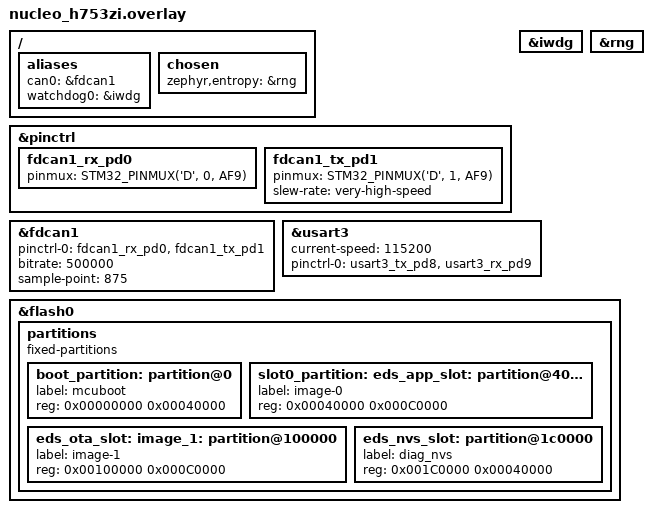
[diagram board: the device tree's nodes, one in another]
/*
 * =============================================================================
 * Xaloqi EDS
 * boards/nucleo_h743zi/nucleo_h743zi.overlay
 *
 * Device Tree overlay for the STMicroelectronics NUCLEO-H743ZI2 board.
 *
 * PURPOSE: Configures the STM32H743's FDCAN1 peripheral as the diagnostic
 *          CAN channel. FDCAN1 is wired to the CN10 connector on the
 *          NUCLEO-H743ZI2 board, where a CAN transceiver (e.g. TJA1051)
 *          must be connected externally.
 *
 * HARDWARE SETUP:
 *   NUCLEO-H743ZI2 → CAN Transceiver (TJA1051 or equivalent)
 *   PD0  (FDCAN1_RX)  → TJA1051 RXD
 *   PD1  (FDCAN1_TX)  → TJA1051 TXD
 *   3.3V               → TJA1051 VCC (via 3.3V regulator)
 *   GND                → TJA1051 GND
 *   TJA1051 CANH/CANL → OBD-II or automotive CAN bus
 *
 * CAN BUS PARAMETERS:
 *   Bus speed: 500 kbit/s  (ISO 15765-4 §4.2 for 11-bit CAN IDs)
 *   Sample point: 87.5%   (matches CANopen and automotive ECU convention)
 *
 * PINMUX:
 *   PD0 / PD1 are the default FDCAN1 pins on STM32H7 series.
 *   Alternative pins (PH13/PH14 on NUCLEO-H743ZI2 CN10) can be used by
 *   replacing pinctrl-0 with &fdcan1_rx_ph13 and &fdcan1_tx_ph14.
 *
 * WATCHDOG:
 *   The IWDG (Independent Watchdog) is enabled with a 100 ms window,
 *   matching CONFIG_DIAG_WDT_WINDOW_MS in prj.conf.
 *   The IWDG clock source is LSI (~32 kHz); prescaler and reload values
 *   are computed by the Zephyr IWDG driver from the window-ms property.
 *
 * SAFETY: This overlay is a starting point. OEM integration must:
 *   [ ] Verify PD0/PD1 pinout against actual board schematic
 *   [ ] Validate 500 kbit/s sample point against network analyser
 *   [ ] Enable CAN termination resistor (120 Ω) on bus endpoints
 *   [ ] Qualify FDCAN1 against ISO 11898-1 electrical requirements
 * =============================================================================
 */

#include <zephyr/dt-bindings/pinctrl/stm32-pinctrl.h>

/* ── Pin control for FDCAN1 ────────────────────────────────────────────────
 *
 * PD0 = FDCAN1_RX (AF9)
 * PD1 = FDCAN1_TX (AF9)
 *
 * Both pins configured as:
 *   - slew-rate = "very-high-speed"  (required for CAN signal integrity)
 *   - drive-open-drain = no          (push-pull for TX, input for RX)
 * ─────────────────────────────────────────────────────────────────────────── */
&pinctrl {
	fdcan1_rx_pd0: fdcan1_rx_pd0 {
		pinmux = <STM32_PINMUX('D', 0, AF9)>;
	};
	fdcan1_tx_pd1: fdcan1_tx_pd1 {
		pinmux = <STM32_PINMUX('D', 1, AF9)>;
		slew-rate = "very-high-speed";
	};
};

/* ── FDCAN1 node ────────────────────────────────────────────────────────────
 *
 * Configures the STM32H743 FDCAN1 controller for classic CAN 2.0B operation
 * at 500 kbit/s. FDCAN FD-mode is deliberately disabled (classic frames only)
 * to match ISO 15765-4 11-bit addressing requirements.
 * ─────────────────────────────────────────────────────────────────────────── */
&fdcan1 {
	status = "okay";
	pinctrl-0 = <&fdcan1_rx_pd0 &fdcan1_tx_pd1>;
	pinctrl-names = "default";

	/*
	 * Sample point = 87.5% — standard automotive ECU configuration.
	 * Computed as: (1 + prop-seg + phase-seg1) / (1 + prop-seg + phase-seg1 + phase-seg2)
	 *
	 * With FDCAN1 kernel clock at 80 MHz and prescaler=1:
	 *   Bit time = 160 time quanta (TQ)
	 *   prop-seg + phase-seg1 = 139 TQ
	 *   phase-seg2            =  20 TQ
	 *   Sample point = 140/160 = 87.5%
	 *
	 * FIX (#309): `bus-speed` was REMOVED here, on the belief that it was
	 *      deprecated-and-dropped and that bus speed comes from the clock
	 *      tree. Both were wrong. Zephyr's dts/bindings/can/can-controller.yaml
	 *      says bus-speed was "renamed to bitrate" — a rename, not a removal —
	 *      and that when no bitrate property is present the controller falls
	 *      back to CONFIG_CAN_DEFAULT_BITRATE, whose Zephyr default is
	 *      125000. So this node silently ran the diagnostic bus at 125 kbit/s
	 *      while every doc, comment and TestLab campaign specified 500 kbit/s,
	 *      and no tester following the documentation could talk to the ECU.
	 *      Measured on target before the fix: FDCAN1_NBTP = 0x12038A13, i.e.
	 *      NBRP=3 (prescaler 4) x 160 tq @ 80 MHz = 125 kbit/s.
	 *      Use `bitrate` (below); do not delete it to silence a deprecation.
	 * FIX: rx-fifo0-elements and tx-fifo-elements removed — these properties are
	 *      not declared in st,stm32h7-fdcan.yaml for Zephyr 3.7 and cause a
	 *      fatal gen_defines.py error: "not declared in 'properties:'".
	 */
	bitrate      = <500000>;   /* ISO 15765-4 diagnostic bus speed */
	sample-point = <875>;
};

/* ── Alias: can0 → fdcan1 ───────────────────────────────────────────────────
 *
 * main.c uses DEVICE_DT_GET(DT_ALIAS(can0)) — this alias maps that to FDCAN1.
 * ─────────────────────────────────────────────────────────────────────────── */
/ {
	aliases {
		can0 = &fdcan1;
		watchdog0 = &iwdg;
	};
};

/* ── Independent Watchdog (IWDG) ────────────────────────────────────────────
 *
 * STM32H743 IWDG is clocked by LSI (~32 kHz, factory-trimmed to ±10%).
 * The Zephyr IWDG driver converts the wdt_timeout_cfg.window.max value
 * (in ms) to prescaler and reload register values automatically.
 *
 * 100 ms window: gives 100 poll iterations at 1 ms/iteration before reset.
 * ─────────────────────────────────────────────────────────────────────────── */
&iwdg {
	status = "okay";
};

/* ── Hardware RNG (STM32H743 true random number generator) ─────────────────
 *
 * Enables the STM32H743ZI hardware RNG peripheral and maps it to the
 * zephyr,entropy chosen node. This allows CONFIG_ENTROPY_GENERATOR=y to
 * link the entropy driver and provide TRNG-backed seed generation for the
 * UDS SecurityAccess AES-CMAC algorithm (Phase 1).
 *
 * The STM32H743ZI has a 32-bit hardware TRNG (HASH/RNG block) seeded by
 * multiple on-chip analogue noise sources. Zephyr driver: st,stm32-rng.
 *
 * FIX (Phase 1 CI): CONFIG_ENTROPY_GENERATOR=y is now set in nucleo_h743zi.conf.
 *   Without this node, DT_HAS_CHOSEN(zephyr_entropy)=1 (built-in board DTS)
 *   but the entropy driver would not be linked → __device_dts_ord_N undefined.
 * ─────────────────────────────────────────────────────────────────────────── */
&rng {
	status = "okay";
};

/ {
	chosen {
		zephyr,entropy = &rng;
	};
};

/* ── UART3 for logging (ST-Link virtual COM port on NUCLEO-H743ZI2) ─────── */
&usart3 {
	status = "okay";
	current-speed = <115200>;
	pinctrl-0 = <&usart3_tx_pd8 &usart3_rx_pd9>;
	pinctrl-names = "default";
};

/* ── NVS flash partition for platform/nvm_store.c ───────────────────────────
 *
 * Reserves the last two 128 KB sectors (256 KB total) of the STM32H743ZI's
 * 2 MB internal flash for Zephyr NVS (Non-Volatile Storage).
 *
 * STM32H743ZI dual-bank flash layout (2 MB total, base 0x08000000):
 *   Bank 1: sectors 0–7  → 0x08000000 – 0x080FFFFF  (8 × 128 KB)
 *   Bank 2: sectors 8–15 → 0x08100000 – 0x081FFFFF  (8 × 128 KB)
 *
 * NVS partition occupies the last 2 sectors of Bank 2:
 *   Flash-relative offset: 0x001C0000  (1.75 MB from flash base)
 *   Size: 0x00040000  (256 KB = 2 × 128 KB sectors)
 *   Physical address: 0x081C0000 – 0x081FFFFF
 *
 * Zephyr NVS requires a minimum of 2 sectors for wear levelling.
 * Two 128 KB sectors provide ample space for the six NVM keys used by this
 * application (security counters, DTC mirror, session stats, lifecycle
 * counter, schema version — all well under 1 KB total).
 *
 * nvm_store_init() receives the flash device pointer and partition offset at
 * runtime via the nvm_store_cfg_t parameter passed from main.c using the
 * FIXED_PARTITION_DEVICE(diag_nvs) and FIXED_PARTITION_OFFSET(diag_nvs)
 * DTS accessor macros.
 *
 * NOTE: The application firmware image must remain below 768 KB (0xC0000
 * bytes, the image-0 slot size below) to avoid overwriting image-1. The
 * basic_ecu firmware is comfortably within this limit (< 256 KB for a
 * typical Zephyr application).
 * =============================================================================
 */
/* ── Flash partition table ───────────────────────────────────────────────────
 *
 * STM32H753ZI dual-bank flash: 2 MB total, base 0x08000000.
 *   Bank 1: sectors 0–7  → 0x08000000–0x080FFFFF  (8 × 128 KB)
 *   Bank 2: sectors 8–15 → 0x08100000–0x081FFFFF  (8 × 128 KB)
 *
 * Layout (exactly 2 MB, every boundary on a 128 KB sector edge):
 *
 *   Offset     Size    Sectors  Label        Purpose
 *   ─────────  ──────  ───────  ───────────  ─────────────────────────────
 *   0x000000   256 KB  2        boot_partition  MCUboot itself (measured
 *                                                ~44.8 KB signed w/ RSA-2048;
 *                                                256 KB leaves headroom).
 *   0x040000   768 KB  6        image-0      Primary firmware slot.
 *   0x100000   768 KB  6        image-1      Secondary / OTA staging slot.
 *                                            platform/zephyr_flash_ops.c
 *                                            writes DFU payloads here via
 *                                            FLASH_AREA_ID(image_1).
 *   0x1C0000   256 KB  2        diag_nvs     Zephyr NVS (security counters,
 *                                            DTC mirror, session stats).
 *                                            Needs ≥ 2 sectors for WL.
 *
 * FIX (H753ZI bring-up, 2026-09-25): previous layout had NO boot_partition —
 * image-0 started at flash base 0x0, identical to where MCUboot's own build
 * also links (zephyr,code-partition resolves to whatever &boot_partition or
 * &slot0_partition points at; with no boot_partition node, MCUboot silently
 * fell back to slot0_partition and would have overwritten the app image on
 * flash, confirmed by inspecting a real MCUboot build's .config
 * (CONFIG_FLASH_LOAD_OFFSET=0x0, same as the app). image-0/image-1 shrank
 * from 896 KB to 768 KB each to make room while keeping every partition
 * boundary sector-aligned — 896/192/64 KB splits are NOT multiples of the
 * 128 KB hardware sector size, which would let a sector erase (NVS wear-
 * levelling, or MCUboot's own writes) corrupt the tail of the neighbouring
 * partition. slot0/slot1 MUST stay equal size (MCUboot swap requirement).
 *
 * FIX (CI 2026-03-30): previous layout had label "mcuboot" on the app slot and
 * no image-1 partition. FLASH_AREA_ID(image_1) in zephyr_flash_ops.c requires
 * a partition labelled "image-1" to exist in the DTS; without it the macro
 * expands to an undeclared identifier → compile error. CONFIG_FLASH_MAP=y is
 * already set in nucleo_h743zi.conf; the DTS label was the only missing piece.
 */
&flash0 {
	/* [FIX] Delete the existing partitions node defined in the Zephyr base board DTS
	 * (nucleo_h743zi2.dts) before redefining it.  The base DTS already has a node
	 * labelled slot0_partition at partition@40000.  Our overlay was adding another
	 * slot0_partition at partition@0, causing:
	 *   devicetree error: Label 'slot0_partition' appears on partition@0 AND partition@40000
	 * Fix: /delete-node/ removes the existing child, then we redefine from scratch
	 * using unique DTS node names (eds_app_slot, eds_ota_slot, eds_nvs_slot) that
	 * cannot conflict with the base board DTS.
	 * FLASH_AREA_ID() resolves by the "label" property string, not the DTS node name,
	 * so FLASH_AREA_ID(image_1) still resolves correctly. */
	/delete-node/ partitions;

	partitions {
		compatible = "fixed-partitions";
		#address-cells = <1>;
		#size-cells = <1>;

		/* MCUboot itself — 256 KB (2 sectors) at flash base. Required so
		 * zephyr,code-partition resolves to &boot_partition (not
		 * &slot0_partition) when MCUboot's OWN build applies its
		 * bootloader/mcuboot/boot/zephyr/app.overlay, which sets exactly
		 * that chosen override. Without this node that override dangles
		 * and MCUboot silently falls back to whatever /chosen already
		 * pointed at (slot0_partition) — linking MCUboot at the same
		 * address as the app image. See the FIX note above the flash
		 * partition table for how this was caught on real hardware. */
		boot_partition: partition@0 {
			label = "mcuboot";
			reg = <0x00000000 0x00040000>;
		};

		/* Primary firmware image slot — 768 KB, starting after boot_partition.
		 * Dual-labelled: eds_app_slot (unique, avoids base-DTS conflict at @40000)
		 * AND slot0_partition (satisfies the Zephyr base board DTS /chosen node:
		 *   zephyr,code-partition = &slot0_partition
		 * Without the slot0_partition label here that /chosen reference is
		 * "undefined node label 'slot0_partition'" after our /delete-node/). */
		slot0_partition: eds_app_slot: partition@40000 {
			label = "image-0";
			reg = <0x00040000 0x000C0000>;
		};

		/* Secondary / OTA staging slot — 768 KB after image-0. MUST stay the
		 * same size as image-0 (MCUboot swap requirement).
		 * platform/zephyr_flash_ops.c targets this via
		 * FIXED_PARTITION_ID(image_1) (see that file's own history note —
		 * this was FLASH_AREA_ID before the actual Zephyr v3.7.0 API was
		 * confirmed), which resolves by DTS NODE LABEL, not by the
		 * "image-1" string "label" property (same node-label-vs-string-
		 * label distinction already documented above for
		 * slot0_partition/eds_app_slot).
		 *
		 * TRIPLE-labelled, same reasoning as slot0_partition above, but
		 * one label further: MCUboot's OWN bootutil library code (not this
		 * repo's — modules/mcuboot/boot/bootutil/src/bootutil_public.c,
		 * pulled in once CONFIG_MCUBOOT_IMG_MANAGER correctly resolves)
		 * hardcodes DT_NODELABEL(slot1_partition) internally to find the
		 * secondary slot — the CANONICAL MCUboot label, distinct from both
		 * eds_ota_slot (this repo's own unique name) and image_1 (what
		 * this repo's own FIXED_PARTITION_ID(image_1) call needs). All
		 * three were needed; found one at a time across CI #291's several
		 * iterations as each successive layer of the build was reached for
		 * the first time (this file's own copy under
		 * examples/safeboot_ecu/boards/ is what that job actually uses —
		 * kept identical here since both files are meant to be exact
		 * copies). This node was simply never given ANY of them until
		 * now. */
		eds_ota_slot: image_1: slot1_partition: partition@100000 {
			label = "image-1";
			reg = <0x00100000 0x000C0000>;
		};

		/* NVS key-value store — last 256 KB (2 × 128 KB sectors). */
		eds_nvs_slot: partition@1c0000 {
			label = "diag_nvs";
			reg = <0x001C0000 0x00040000>;
		};
	};
};
